# ESP32S31_RADIO register map
Vendor: Espressif; Series: ESP32-S31; File version: 3.52
Registers are 32-bit, read-write, no defined reset value unless marked. A register's access mark holds for its fields unless they carry their own. Offsets are from the block's base; [hi:lo] are bit positions; {n}, {i} and the like mark numbered series.

## WIFI_MAC_CONTROL — Shared MAC run/stop control. The cold open-RX frontier publishes zero; the complete vendor channel-switch chain requests quiescence here and later restarts the no-power-save profile.
Base 0x20104CAC
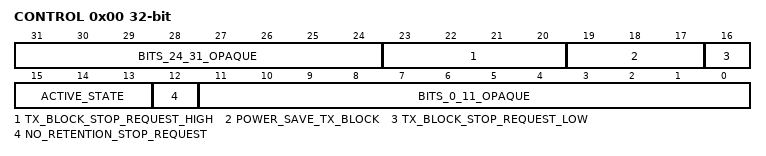
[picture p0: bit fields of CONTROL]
0x00 CONTROL — Project-assigned name. Cold promiscuous initialization writes zero. libpp[hal_mac.o]::hal_mac_deinit records bits 13 and 14 as TX/RX activity and sets bit 12 plus bits 23:16; hal_mac_init with WIFI_PS_NONE clears that same stop-request mask.
  [31:24] BITS_24_31_OPAQUE — Opaque: meaning not established.
  [23:20] TX_BLOCK_STOP_REQUEST_HIGH — Project-assigned name. Bits 23:20 of the eight stop-request bits libpp[hal_mac.o]::hal_mac_deinit sets and hal_mac_init clears with the WIFI_PS_NONE retention mask.
  [19:17] POWER_SAVE_TX_BLOCK — Project-assigned name. Bits 19:17 of the stop-request bits. The vendor power manager sets all three to block the TX queues when its coexistence slice ends and clears them to unblock; its retention mask keeps them out of the MAC deinit and init requests while an associated station runs power management.
    0=RUN (The TX queues run.); 7=BLOCKED (The TX queues are blocked.)
  [16] TX_BLOCK_STOP_REQUEST_LOW — Project-assigned name. Bit 16 of the eight stop-request bits libpp[hal_mac.o]::hal_mac_deinit sets and hal_mac_init clears with the WIFI_PS_NONE retention mask.
  [15:13] ACTIVE_STATE ro — Project-assigned name. Three-bit activity state polled until zero before PHY retuning. libpp[hal_mac.o]::hal_mac_deinit independently records bit 13 as TX active and bit 14 as RX active; bit 15 remains unnamed.
  [12] NO_RETENTION_STOP_REQUEST — Project-assigned name. Included in the MAC stop request and cleared by hal_mac_init for the WIFI_PS_NONE all-ones retention mask.
  [11:0] BITS_0_11_OPAQUE — Opaque: meaning not established.

## WIFI_MAC_REGDMA_CONTROL — Shared WDEVPWR control word. The channel-change leaf proves the REGDMA selector, while complete modem-power leaves prove the wake-protect lead time and TBTT auto-period fields. Hardware interactions between these fields remain unqualified.
Base 0x2010D83C
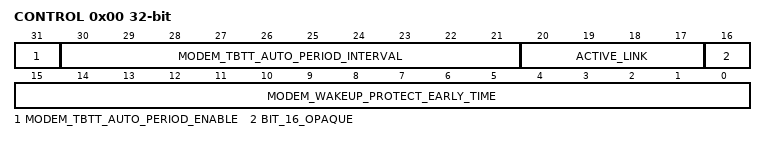
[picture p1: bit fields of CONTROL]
0x00 CONTROL — Project-assigned name. Shared REGDMA and modem wakeup configuration word. Every promoted field has a complete independent setter; their combined hardware lifecycle is not inferred.
  [31] MODEM_TBTT_AUTO_PERIOD_ENABLE — Project-assigned name. The dedicated enable and disable leaves set or clear bit 31.
  [30:21] MODEM_TBTT_AUTO_PERIOD_INTERVAL — Project-assigned name. libpp[hal_pwr.o]::pwr_hal_set_mac_modem_tbtt_auto_period_interval replaces bits 30:21 from the low ten argument bits.
  [20:17] ACTIVE_LINK — Project-assigned name. Four-bit Wi-Fi MAC REGDMA link selector; the active no-power-save channel restart writes four. Leaving zero after retuning caused intermittent authentication ACK timeouts.
    on write: 4=WIFI_NO_POWER_SAVE (REGDMA link selected by the qualified Wi-Fi no-power-save restart.)
  [16] BIT_16_OPAQUE — Opaque: meaning not established.
  [15:0] MODEM_WAKEUP_PROTECT_EARLY_TIME — Project-assigned name. libpp[hal_pwr.o]::pwr_hal_set_mac_modem_state_wakeup_protect_early_time replaces the low sixteen bits.

## WIFI_MAC_KEY_TABLE — Twenty-five entries of ten 32-bit words. Complete hal_crypto_clr_key_entry proves the 0x28-byte stride and all ten ordered stores; set/get leaves prove the peer/control/key layout.
Base 0x20105800
{0x0+4i} ENTRY_WORD{i} (i=0..249) — Project-assigned name. Flat key-table word; entry is index/10 and word is index%10. Words zero and one carry peer/control, later words carry key material for the recovered CCMP transaction.
  [31:0] VALUE — Project-assigned name.
